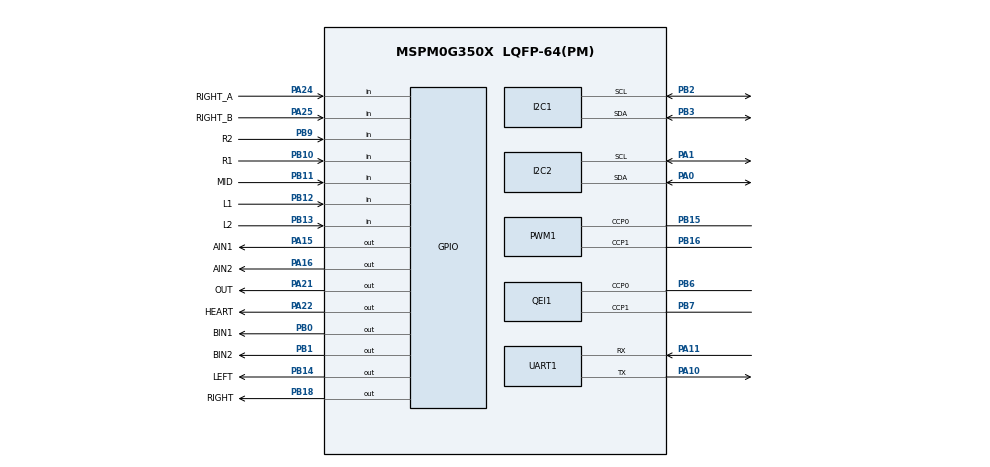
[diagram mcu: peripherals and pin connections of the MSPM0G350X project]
/**
 * @cliArgs --device "MSPM0G350X" --part "Default" --package "LQFP-64(PM)" --product "mspm0_sdk@2.11.00.07"
 * @versions {"tool":"1.26.2+4477"}
 */

/**
 * Import the modules used in this configuration.
 */
const GPIO   = scripting.addModule("/ti/driverlib/GPIO", {}, false);
const GPIO1  = GPIO.addInstance();
const GPIO2  = GPIO.addInstance();
const GPIO3  = GPIO.addInstance();
const GPIO4  = GPIO.addInstance();
const GPIO5  = GPIO.addInstance();
const I2C    = scripting.addModule("/ti/driverlib/I2C", {}, false);
const I2C1   = I2C.addInstance();
const I2C2   = I2C.addInstance();
const PWM    = scripting.addModule("/ti/driverlib/PWM", {}, false);
const PWM1   = PWM.addInstance();
const QEI    = scripting.addModule("/ti/driverlib/QEI", {}, false);
const QEI1   = QEI.addInstance();
const SYSCTL = scripting.addModule("/ti/driverlib/SYSCTL");
const TIMER  = scripting.addModule("/ti/driverlib/TIMER", {}, false);
const TIMER1 = TIMER.addInstance();
const UART   = scripting.addModule("/ti/driverlib/UART", {}, false);
const UART1  = UART.addInstance();

/**
 * Write custom configuration values to the imported modules.
 */
GPIO1.$name                          = "GPIO_MOTOR";
GPIO1.associatedPins.create(4);
GPIO1.associatedPins[0].$name        = "AIN1";
GPIO1.associatedPins[0].initialValue = "SET";
GPIO1.associatedPins[0].pin.$assign  = "PA15";
GPIO1.associatedPins[1].$name        = "AIN2";
GPIO1.associatedPins[1].initialValue = "SET";
GPIO1.associatedPins[1].pin.$assign  = "PA16";
GPIO1.associatedPins[2].$name        = "BIN1";
GPIO1.associatedPins[2].initialValue = "SET";
GPIO1.associatedPins[2].pin.$assign  = "PB0";
GPIO1.associatedPins[3].$name        = "BIN2";
GPIO1.associatedPins[3].initialValue = "SET";
GPIO1.associatedPins[3].pin.$assign  = "PB1";

const Board = scripting.addModule("/ti/driverlib/Board", {}, false);

GPIO2.$name                         = "GPIO_LED";
GPIO2.associatedPins.create(3);
GPIO2.associatedPins[0].$name       = "HEART";
GPIO2.associatedPins[0].pin.$assign = "PA22";
GPIO2.associatedPins[1].$name       = "LEFT";
GPIO2.associatedPins[1].pin.$assign = "PB14";
GPIO2.associatedPins[2].$name       = "RIGHT";
GPIO2.associatedPins[2].pin.$assign = "PB18";

GPIO3.$name                         = "GPIO_BUZZER";
GPIO3.associatedPins[0].$name       = "OUT";
GPIO3.associatedPins[0].pin.$assign = "PA21";

GPIO4.$name                              = "GPIO_LINE";
GPIO4.associatedPins.create(5);
GPIO4.associatedPins[0].$name            = "L2";
GPIO4.associatedPins[0].direction        = "INPUT";
GPIO4.associatedPins[0].internalResistor = "PULL_DOWN";
GPIO4.associatedPins[0].pin.$assign      = "PB13";
GPIO4.associatedPins[1].$name            = "L1";
GPIO4.associatedPins[1].direction        = "INPUT";
GPIO4.associatedPins[1].internalResistor = "PULL_DOWN";
GPIO4.associatedPins[1].pin.$assign      = "PB12";
GPIO4.associatedPins[2].$name            = "MID";
GPIO4.associatedPins[2].internalResistor = "PULL_DOWN";
GPIO4.associatedPins[2].direction        = "INPUT";
GPIO4.associatedPins[2].pin.$assign      = "PB11";
GPIO4.associatedPins[3].$name            = "R1";
GPIO4.associatedPins[3].internalResistor = "PULL_DOWN";
GPIO4.associatedPins[3].direction        = "INPUT";
GPIO4.associatedPins[3].pin.$assign      = "PB10";
GPIO4.associatedPins[4].$name            = "R2";
GPIO4.associatedPins[4].internalResistor = "PULL_DOWN";
GPIO4.associatedPins[4].direction        = "INPUT";
GPIO4.associatedPins[4].pin.$assign      = "PB9";

GPIO5.$name                              = "GPIO_ENCODER";
GPIO5.associatedPins.create(2);
GPIO5.associatedPins[0].direction        = "INPUT";
GPIO5.associatedPins[0].internalResistor = "PULL_DOWN";
GPIO5.associatedPins[0].polarity         = "RISE_FALL";
GPIO5.associatedPins[0].$name            = "RIGHT_A";
GPIO5.associatedPins[0].interruptEn      = true;
GPIO5.associatedPins[0].pin.$assign      = "PA24";
GPIO5.associatedPins[1].$name            = "RIGHT_B";
GPIO5.associatedPins[1].direction        = "INPUT";
GPIO5.associatedPins[1].interruptEn      = true;
GPIO5.associatedPins[1].polarity         = "RISE_FALL";
GPIO5.associatedPins[1].internalResistor = "PULL_DOWN";
GPIO5.associatedPins[1].pin.$assign      = "PA25";

I2C1.$name                             = "OLED_I2C";
I2C1.basicEnableController             = true;
I2C1.basicControllerStandardBusSpeed   = "Fast";
I2C1.peripheral.$assign                = "I2C1";
I2C1.peripheral.sdaPin.$assign         = "PB3";
I2C1.peripheral.sclPin.$assign         = "PB2";
I2C1.sdaPinConfig.$name                = "ti_driverlib_gpio_GPIOPinGeneric4";
I2C1.sdaPinConfig.hideOutputInversion  = scripting.forceWrite(false);
I2C1.sdaPinConfig.onlyInternalResistor = scripting.forceWrite(false);
I2C1.sdaPinConfig.passedPeripheralType = scripting.forceWrite("Digital");
I2C1.sclPinConfig.$name                = "ti_driverlib_gpio_GPIOPinGeneric5";
I2C1.sclPinConfig.hideOutputInversion  = scripting.forceWrite(false);
I2C1.sclPinConfig.onlyInternalResistor = scripting.forceWrite(false);
I2C1.sclPinConfig.passedPeripheralType = scripting.forceWrite("Digital");

I2C2.$name                             = "IMU_I2C";
I2C2.basicEnableController             = true;
I2C2.basicControllerStandardBusSpeed   = "Fast";
I2C2.peripheral.$assign                = "I2C0";
I2C2.peripheral.sdaPin.$assign         = "PA0";
I2C2.peripheral.sclPin.$assign         = "PA1";
I2C2.sdaPinConfig.$name                = "ti_driverlib_gpio_GPIOPinGeneric6";
I2C2.sdaPinConfig.hideOutputInversion  = scripting.forceWrite(false);
I2C2.sdaPinConfig.onlyInternalResistor = scripting.forceWrite(false);
I2C2.sdaPinConfig.passedPeripheralType = scripting.forceWrite("Digital");
I2C2.sclPinConfig.$name                = "ti_driverlib_gpio_GPIOPinGeneric7";
I2C2.sclPinConfig.hideOutputInversion  = scripting.forceWrite(false);
I2C2.sclPinConfig.onlyInternalResistor = scripting.forceWrite(false);
I2C2.sclPinConfig.passedPeripheralType = scripting.forceWrite("Digital");

PWM1.$name                              = "MOTOR_PWM";
PWM1.timerCount                         = 1600;
PWM1.peripheral.$assign                 = "TIMG7";
PWM1.peripheral.ccp0Pin.$assign         = "PB15";
PWM1.peripheral.ccp1Pin.$assign         = "PB16";
PWM1.PWM_CHANNEL_0.$name                = "ti_driverlib_pwm_PWMTimerCC0";
PWM1.PWM_CHANNEL_0.shadowUpdateMode     = "ZERO_EVT";
PWM1.PWM_CHANNEL_1.$name                = "ti_driverlib_pwm_PWMTimerCC1";
PWM1.PWM_CHANNEL_1.shadowUpdateMode     = "ZERO_EVT";
PWM1.ccp0PinConfig.$name                = "ti_driverlib_gpio_GPIOPinGeneric0";
PWM1.ccp0PinConfig.direction            = scripting.forceWrite("OUTPUT");
PWM1.ccp0PinConfig.hideOutputInversion  = scripting.forceWrite(false);
PWM1.ccp0PinConfig.onlyInternalResistor = scripting.forceWrite(false);
PWM1.ccp0PinConfig.passedPeripheralType = scripting.forceWrite("Digital");
PWM1.ccp1PinConfig.$name                = "ti_driverlib_gpio_GPIOPinGeneric1";
PWM1.ccp1PinConfig.direction            = scripting.forceWrite("OUTPUT");
PWM1.ccp1PinConfig.hideOutputInversion  = scripting.forceWrite(false);
PWM1.ccp1PinConfig.onlyInternalResistor = scripting.forceWrite(false);
PWM1.ccp1PinConfig.passedPeripheralType = scripting.forceWrite("Digital");

QEI1.$name                              = "ENCODER_LEFT";
QEI1.peripheral.ccp0Pin.$assign         = "PB6";
QEI1.peripheral.ccp1Pin.$assign         = "PB7";
QEI1.ccp0PinConfig.$name                = "ti_driverlib_gpio_GPIOPinGeneric2";
QEI1.ccp0PinConfig.hideOutputInversion  = scripting.forceWrite(false);
QEI1.ccp0PinConfig.onlyInternalResistor = scripting.forceWrite(false);
QEI1.ccp0PinConfig.passedPeripheralType = scripting.forceWrite("Digital");
QEI1.ccp1PinConfig.$name                = "ti_driverlib_gpio_GPIOPinGeneric3";
QEI1.ccp1PinConfig.hideOutputInversion  = scripting.forceWrite(false);
QEI1.ccp1PinConfig.onlyInternalResistor = scripting.forceWrite(false);
QEI1.ccp1PinConfig.passedPeripheralType = scripting.forceWrite("Digital");

SYSCTL.forceDefaultClkConfig = true;
SYSCTL.clockTreeEn           = true;

TIMER1.$name              = "CONTROL_TIMER";
TIMER1.timerClkPrescale   = 32;
TIMER1.timerMode          = "PERIODIC";
TIMER1.timerPeriod        = "10 ms";
TIMER1.interrupts         = ["ZERO"];
TIMER1.peripheral.$assign = "TIMG0";

UART1.$name                            = "DEBUG_UART";
UART1.targetBaudRate                   = 115200;
UART1.peripheral.$assign               = "UART0";
UART1.peripheral.rxPin.$assign         = "PA11";
UART1.peripheral.txPin.$assign         = "PA10";
UART1.txPinConfig.$name                = "ti_driverlib_gpio_GPIOPinGeneric8";
UART1.txPinConfig.direction            = scripting.forceWrite("OUTPUT");
UART1.txPinConfig.hideOutputInversion  = scripting.forceWrite(false);
UART1.txPinConfig.onlyInternalResistor = scripting.forceWrite(false);
UART1.txPinConfig.passedPeripheralType = scripting.forceWrite("Digital");
UART1.rxPinConfig.$name                = "ti_driverlib_gpio_GPIOPinGeneric9";
UART1.rxPinConfig.hideOutputInversion  = scripting.forceWrite(false);
UART1.rxPinConfig.onlyInternalResistor = scripting.forceWrite(false);
UART1.rxPinConfig.passedPeripheralType = scripting.forceWrite("Digital");

/**
 * Pinmux solution for unlocked pins/peripherals. This ensures that minor changes to the automatic solver in a future
 * version of the tool will not impact the pinmux you originally saw.  These lines can be completely deleted in order to
 * re-solve from scratch.
 */
Board.peripheral.$suggestSolution          = "DEBUGSS";
Board.peripheral.swclkPin.$suggestSolution = "PA20";
Board.peripheral.swdioPin.$suggestSolution = "PA19";
QEI1.peripheral.$suggestSolution           = "TIMG8";
